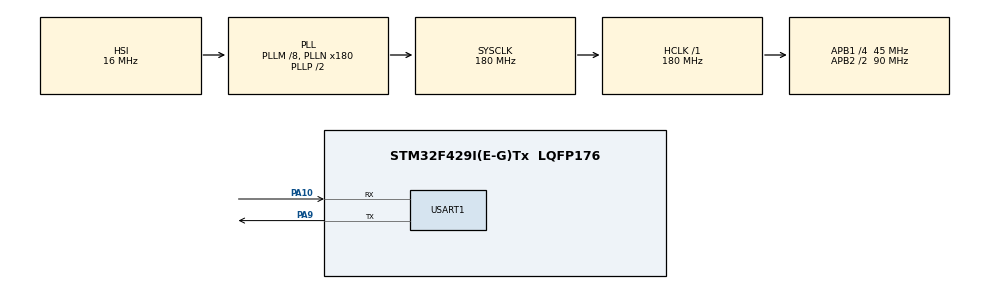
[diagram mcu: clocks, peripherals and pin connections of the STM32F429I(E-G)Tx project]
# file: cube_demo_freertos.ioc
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FREERTOS.Tasks01=defaultTask,0,128,StartDefaultTask,Default,NULL,Dynamic,NULL,NULL;talker_task,-3,128,talker,Default,NULL,Dynamic,NULL,NULL;listener_task,-3,128,listener,Default,NULL,Dynamic,NULL,NULL
Mcu.Family=STM32F4
Mcu.Name=STM32F429I(E-G)Tx
Mcu.Package=LQFP176
NVIC.PriorityGroup=NVIC_PRIORITYGROUP_4
NVIC.TIM8_TRG_COM_TIM14_IRQn=true\:0\:0\:false\:false\:true\:false\:false\:true
NVIC.TimeBase=TIM8_TRG_COM_TIM14_IRQn
NVIC.TimeBaseIP=TIM14
PA10.Mode=Asynchronous
PA10.Signal=USART1_RX
PA13.Mode=Serial_Wire
PA13.Signal=SYS_JTMS-SWDIO
PA14.Mode=Serial_Wire
PA14.Signal=SYS_JTCK-SWCLK
PA9.Mode=Asynchronous
PA9.Signal=USART1_TX
PH0/OSC_IN.Mode=HSE-External-Oscillator
PH0/OSC_IN.Signal=RCC_OSC_IN
PH1/OSC_OUT.Mode=HSE-External-Oscillator
PH1/OSC_OUT.Signal=RCC_OSC_OUT
ProjectManager.HeapSize=0x200
ProjectManager.StackSize=0x400
ProjectManager.TargetToolchain=MDK-ARM V5
RCC.48MHZClocksFreq_Value=90000000
RCC.AHBFreq_Value=180000000
RCC.APB1CLKDivider=RCC_HCLK_DIV4
RCC.APB1Freq_Value=45000000
RCC.APB1TimFreq_Value=90000000
RCC.APB2CLKDivider=RCC_HCLK_DIV2
RCC.APB2Freq_Value=90000000
RCC.APB2TimFreq_Value=180000000
RCC.CortexFreq_Value=180000000
RCC.HCLKFreq_Value=180000000
RCC.HSE_VALUE=25000000
RCC.HSI_VALUE=16000000
RCC.LSE_VALUE=32768
RCC.PLLM=8
RCC.PLLN=180
RCC.SYSCLKFreq_VALUE=180000000
RCC.SYSCLKSource=RCC_SYSCLKSOURCE_PLLCLK
RCC.VCOOutputFreq_Value=360000000
USART1.VirtualMode=VM_ASYNC
VP_FREERTOS_VS_CMSIS_V1.Mode=CMSIS_V1
VP_SYS_VS_tim14.Mode=TIM14
board=custom

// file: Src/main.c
/* USER CODE BEGIN Header */
/**
  ******************************************************************************
  * @file           : main.c
  * @brief          : Main program body
  ******************************************************************************
  * @attention
  *
  * <h2><center>&copy; Copyright (c) 2019 STMicroelectronics.
  * All rights reserved.</center></h2>
  *
  * This software component is licensed by ST under Ultimate Liberty license
  * SLA0044, the "License"; You may not use this file except in compliance with
  * the License. You may obtain a copy of the License at:
  *                             www.st.com/SLA0044
  *
  ******************************************************************************
  */
/* USER CODE END Header */

#include "main.h"
#include "cmsis_os.h"
#include "usart.h"
#include "gpio.h"

void SystemClock_Config(void);
void MX_FREERTOS_Init(void);

int main(void)
{

  /* MCU Configuration--------------------------------------------------------*/

  /* Reset of all peripherals, Initializes the Flash interface and the Systick. */
  HAL_Init();

  /* Configure the system clock */
  SystemClock_Config();

  /* Initialize all configured peripherals */
  MX_GPIO_Init();
  MX_USART1_UART_Init();

  /* Call init function for freertos objects (in freertos.c) */
  MX_FREERTOS_Init();

  /* Start scheduler */
  osKernelStart();

  /* We should never get here as control is now taken by the scheduler */

  /* Infinite loop */
  while (1)
  {

  }
}

void SystemClock_Config(void)
{
  RCC_OscInitTypeDef RCC_OscInitStruct = {0};
  RCC_ClkInitTypeDef RCC_ClkInitStruct = {0};

  /** Configure the main internal regulator output voltage
  */
  __HAL_RCC_PWR_CLK_ENABLE();
  __HAL_PWR_VOLTAGESCALING_CONFIG(PWR_REGULATOR_VOLTAGE_SCALE1);
  /** Initializes the CPU, AHB and APB busses clocks
  */
  RCC_OscInitStruct.OscillatorType = RCC_OSCILLATORTYPE_HSI;
  RCC_OscInitStruct.HSIState = RCC_HSI_ON;
  RCC_OscInitStruct.HSICalibrationValue = RCC_HSICALIBRATION_DEFAULT;
  RCC_OscInitStruct.PLL.PLLState = RCC_PLL_ON;
  RCC_OscInitStruct.PLL.PLLSource = RCC_PLLSOURCE_HSI;
  RCC_OscInitStruct.PLL.PLLM = 8;
  RCC_OscInitStruct.PLL.PLLN = 180;
  RCC_OscInitStruct.PLL.PLLP = RCC_PLLP_DIV2;
  RCC_OscInitStruct.PLL.PLLQ = 4;
  if (HAL_RCC_OscConfig(&RCC_OscInitStruct) != HAL_OK)
  {
    Error_Handler();
  }
  /** Activate the Over-Drive mode
  */
  if (HAL_PWREx_EnableOverDrive() != HAL_OK)
  {
    Error_Handler();
  }
  /** Initializes the CPU, AHB and APB busses clocks
  */
  RCC_ClkInitStruct.ClockType = RCC_CLOCKTYPE_HCLK|RCC_CLOCKTYPE_SYSCLK
                              |RCC_CLOCKTYPE_PCLK1|RCC_CLOCKTYPE_PCLK2;
  RCC_ClkInitStruct.SYSCLKSource = RCC_SYSCLKSOURCE_PLLCLK;
  RCC_ClkInitStruct.AHBCLKDivider = RCC_SYSCLK_DIV1;
  RCC_ClkInitStruct.APB1CLKDivider = RCC_HCLK_DIV4;
  RCC_ClkInitStruct.APB2CLKDivider = RCC_HCLK_DIV2;

  if (HAL_RCC_ClockConfig(&RCC_ClkInitStruct, FLASH_LATENCY_5) != HAL_OK)
  {
    Error_Handler();
  }
}

void HAL_TIM_PeriodElapsedCallback(TIM_HandleTypeDef *htim)
{
  if (htim->Instance == TIM14) {
    HAL_IncTick();
  }
}

void Error_Handler(void)
{
}

/************************ (C) COPYRIGHT STMicroelectronics *****END OF FILE****/

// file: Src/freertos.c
/* USER CODE BEGIN Header */
/**
  ******************************************************************************
  * File Name          : freertos.c
  * Description        : Code for freertos applications
  ******************************************************************************
  * @attention
  *
  * <h2><center>&copy; Copyright (c) 2019 STMicroelectronics.
  * All rights reserved.</center></h2>
  *
  * This software component is licensed by ST under Ultimate Liberty license
  * SLA0044, the "License"; You may not use this file except in compliance with
  * the License. You may obtain a copy of the License at:
  *                             www.st.com/SLA0044
  *
  ******************************************************************************
  */
/* USER CODE END Header */

#include "FreeRTOS.h"
#include "task.h"
#include "main.h"
#include "cmsis_os.h"

/* USER CODE BEGIN Variables */
extern osThreadId blink_taskHandle;
/* USER CODE END Variables */
osThreadId defaultTaskHandle;
osThreadId talker_taskHandle;
osThreadId listener_taskHandle;

/* USER CODE BEGIN FunctionPrototypes */
extern void blink(void const * argument);
/* USER CODE END FunctionPrototypes */

void StartDefaultTask(void const * argument);
void talker(void const * argument);
void listener(void const * argument);

void MX_FREERTOS_Init(void); /* (MISRA C 2004 rule 8.1) */

/* GetIdleTaskMemory prototype (linked to static allocation support) */
void vApplicationGetIdleTaskMemory( StaticTask_t **ppxIdleTaskTCBBuffer, StackType_t **ppxIdleTaskStackBuffer, uint32_t *pulIdleTaskStackSize );

/* USER CODE BEGIN GET_IDLE_TASK_MEMORY */
static StaticTask_t xIdleTaskTCBBuffer;
static StackType_t xIdleStack[configMINIMAL_STACK_SIZE];

void vApplicationGetIdleTaskMemory( StaticTask_t **ppxIdleTaskTCBBuffer, StackType_t **ppxIdleTaskStackBuffer, uint32_t *pulIdleTaskStackSize )
{
  *ppxIdleTaskTCBBuffer = &xIdleTaskTCBBuffer;
  *ppxIdleTaskStackBuffer = &xIdleStack[0];
  *pulIdleTaskStackSize = configMINIMAL_STACK_SIZE;
  /* place for user code */
}
/* USER CODE END GET_IDLE_TASK_MEMORY */

void MX_FREERTOS_Init(void) {

  /* Create the thread(s) */
  /* definition and creation of defaultTask */
  osThreadDef(defaultTask, StartDefaultTask, osPriorityNormal, 0, 128);
  defaultTaskHandle = osThreadCreate(osThread(defaultTask), NULL);

  /* definition and creation of talker_task */
  osThreadDef(talker_task, talker, osPriorityIdle, 0, 128);
  talker_taskHandle = osThreadCreate(osThread(talker_task), NULL);

  /* definition and creation of listener_task */
  osThreadDef(listener_task, listener, osPriorityIdle, 0, 128);
  listener_taskHandle = osThreadCreate(osThread(listener_task), NULL);

  /* USER CODE BEGIN RTOS_THREADS */
  /* add threads, ... */
	osThreadDef(blink_task, blink, osPriorityIdle, 0, 128);
  blink_taskHandle = osThreadCreate(osThread(blink_task), NULL);
  /* USER CODE END RTOS_THREADS */

}

void StartDefaultTask(void const * argument)
{

  for(;;)
  {
    osDelay(1);
  }
}

void talker(void const * argument)
{
  /* USER CODE BEGIN talker */
  /* Infinite loop */
  for(;;)
  {
		printf("talk --\r\n");
    osDelay(100);
  }
  /* USER CODE END talker */
}

void listener(void const * argument)
{
  /* USER CODE BEGIN listener */
  /* Infinite loop */
  for(;;)
  {
		printf("listener ---\r\n");
    osDelay(1000);
  }
  /* USER CODE END listener */
}

/************************ (C) COPYRIGHT STMicroelectronics *****END OF FILE****/
